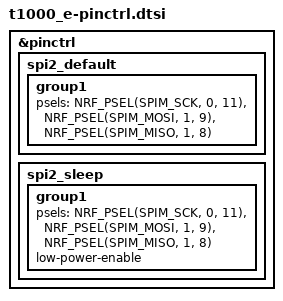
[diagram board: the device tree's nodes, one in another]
/* SPI to the LR1110: SCK P0.11, MOSI P1.09, MISO P1.08. */
&pinctrl {
	spi2_default: spi2_default {
		group1 {
			psels = <NRF_PSEL(SPIM_SCK, 0, 11)>,
				<NRF_PSEL(SPIM_MOSI, 1, 9)>,
				<NRF_PSEL(SPIM_MISO, 1, 8)>;
		};
	};

	spi2_sleep: spi2_sleep {
		group1 {
			psels = <NRF_PSEL(SPIM_SCK, 0, 11)>,
				<NRF_PSEL(SPIM_MOSI, 1, 9)>,
				<NRF_PSEL(SPIM_MISO, 1, 8)>;
			low-power-enable;
		};
	};
};
